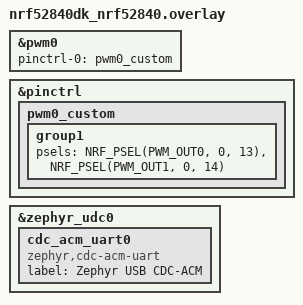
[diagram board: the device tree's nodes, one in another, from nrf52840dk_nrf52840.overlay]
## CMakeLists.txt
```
# SPDX-License-Identifier: Apache-2.0


cmake_minimum_required(VERSION 3.20.0)
find_package(Zephyr REQUIRED HINTS $ENV{ZEPHYR_BASE})
project(nrf52840)

test_sysbuild()

target_sources(app PRIVATE src/main.c)

FILE(GLOB mylib_sources ../lib/*.c)
target_sources(app PRIVATE ${mylib_sources})

# Add the include directory
target_include_directories(app PRIVATE ../include)
```

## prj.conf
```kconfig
CONFIG_GPIO=y
CONFIG_PRINTK=y
CONFIG_PWM=y

CONFIG_LED=y
CONFIG_LED_PWM=y

CONFIG_CBPRINTF_FP_SUPPORT=y


CONFIG_STDOUT_CONSOLE=y
CONFIG_USB_DEVICE_STACK=y
CONFIG_USB_DEVICE_PRODUCT="Zephyr CDC ACM sample"
CONFIG_USB_DEVICE_PID=0x0001
CONFIG_LOG=y
CONFIG_USB_DRIVER_LOG_LEVEL_ERR=y
CONFIG_USB_DEVICE_LOG_LEVEL_ERR=y
CONFIG_SERIAL=y
CONFIG_UART_INTERRUPT_DRIVEN=y
CONFIG_UART_LINE_CTRL=y
CONFIG_USB_DEVICE_INITIALIZE_AT_BOOT=n

CONFIG_BT=y
CONFIG_BT_OBSERVER=y
CONFIG_BT_SETTINGS=n
CONFIG_BT_PERIPHERAL=y
CONFIG_BT_DEVICE_NAME=""

CONFIG_LOG=y
CONFIG_USB_CDC_ACM=y
CONFIG_USB_DEVICE_STACK=y
CONFIG_UART_INTERRUPT_DRIVEN=y
CONFIG_UART_1_INTERRUPT_DRIVEN=y
CONFIG_UART_ASYNC_API=y
CONFIG_UART_LINE_CTRL=y
CONFIG_RING_BUFFER=y
CONFIG_NEWLIB_LIBC=y

CONFIG_GPIO=y
```

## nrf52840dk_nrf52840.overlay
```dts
&pwm0 {
    status = "okay";
    pinctrl-0 = <&pwm0_custom>;
    pinctrl-names = "default", "sleep";
};

&pinctrl {
    pwm0_custom: pwm0_custom {
        group1 {
            psels = <NRF_PSEL(PWM_OUT0, 0, 13)>, <NRF_PSEL(PWM_OUT1, 0, 14)>;
        };
    };
};

&zephyr_udc0 {
	cdc_acm_uart0 {
		compatible = "zephyr,cdc-acm-uart";
		label = "Zephyr USB CDC-ACM";
	};
};
```

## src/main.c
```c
#include <classification.h>
#include <display_data.h>
#include <servo.h>
#include <serial.h>
#include <ultrasonic.h>
#include <zephyr/kernel.h>
#include <zephyr/device.h>
#include <bt.h>
#include <zephyr/bluetooth/bluetooth.h>
#include <zephyr/bluetooth/hci.h>
#include <zephyr/sys/byteorder.h>
#include <zephyr/bluetooth/gap.h>

int main(void) {
    printk("here\n");
    ultrasonic_setup();
    

    // //set up serial code
    serial_init();

     // Initialize Bluetooth
     int err = bt_enable(NULL);
     if (err) {
         printk("Bluetooth init failed (err %d)\n", err);
         return;
     }
 
     printk("Bluetooth initialized\n");

     bt_advertiser_init();

     threads_init();
    
    // test();

    return 0;
}
```
